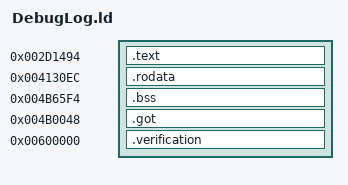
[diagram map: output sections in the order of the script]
OUTPUT_FORMAT("elf32-littlearm")
OUTPUT_ARCH(arm)
ENTRY(_Z14ekd_debug_initv)
INCLUDE build/matches/debug-log/retail-symbols.ld
fopen = 0x001c45bc;
fclose = 0x001c4628;
printf = 0x001c4058;
fprintf = 0x001c4388;
strcpy = 0x001c3fd4;
strlen = 0x001c48bc;
vprintf = 0x001c43c4;
__aeabi_f2d = 0x001c48f8;
__stack_chk_fail = 0x001c42e0;
SECTIONS {
    .text 0x002d1494 : {
        *debug-log.o(.text._Z14ekd_debug_initv)
        *debug-log.o(.text._Z13ekd_debug_outPKcf)
        *debug-log.o(.text._Z13ekd_debug_outPKci)
        *debug-log.o(.text._Z13ekd_debug_outPKcPc)
        *debug-log.o(.text._Z13ekd_debug_outPKc)
        *debug-log.o(.text._Z7dbg_outPcz)
    }
    .rodata 0x004130ec : {
        . = 0x0; *debug-log.o(.rodata.logName)
        . = 0x10; *debug-log.o(.rodata.writeMode)
        . = 0x14; *debug-log.o(.rodata.errorInit)
        . = 0x40; *debug-log.o(.rodata.appendMode)
        . = 0x44; *debug-log.o(.rodata.errorFloat)
        . = 0x88; *debug-log.o(.rodata.errorInt)
        . = 0xcc; *debug-log.o(.rodata.errorString)
        . = 0x110; *debug-log.o(.rodata.errorText)
    }
    .bss 0x004b65f4 : { *debug-log.o(.bss.ekd_isHasInit) }
    .got 0x004b0048 : { *(.got.plt) . = 0x360; *(.got) }
    .verification 0x00600000 : { *retail-got.o(.text) }
}
